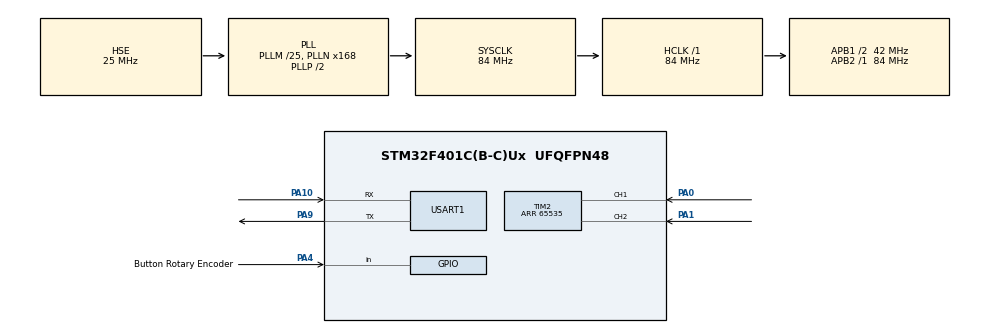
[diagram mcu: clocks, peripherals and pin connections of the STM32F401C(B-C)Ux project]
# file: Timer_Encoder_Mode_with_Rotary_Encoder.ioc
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Mcu.Family=STM32F4
RCC.PLLSourceVirtual=RCC_PLLSOURCE_HSE
RCC.CortexFreq_Value=84000000
PA10.Mode=Asynchronous
TIM2.IC1Filter=10
PH1\ -\ OSC_OUT.Mode=HSE-External-Oscillator
TIM2.EncoderMode=TIM_ENCODERMODE_TI12
RCC.APB1CLKDivider=RCC_HCLK_DIV2
RCC.SYSCLKSource=RCC_SYSCLKSOURCE_PLLCLK
ProjectManager.StackSize=0x400
PA0-WKUP.Signal=S_TIM2_CH1_ETR
PA13.Signal=SYS_JTMS-SWDIO
SH.S_TIM2_CH2.0=TIM2_CH2,Encoder_Interface
PA9.Mode=Asynchronous
PH0\ -\ OSC_IN.Mode=HSE-External-Oscillator
PH0\ -\ OSC_IN.Signal=RCC_OSC_IN
ProjectManager.TargetToolchain=STM32CubeIDE
RCC.HCLKFreq_Value=84000000
RCC.APB2TimFreq_Value=84000000
PA9.Signal=USART1_TX
RCC.LSE_VALUE=32768
PA1.Signal=S_TIM2_CH2
RCC.AHBFreq_Value=84000000
RCC.HSE_VALUE=25000000
PH1\ -\ OSC_OUT.Signal=RCC_OSC_OUT
board=custom
RCC.VCOOutputFreq_Value=168000000
RCC.APB2Freq_Value=84000000
PA14.Mode=Serial_Wire
TIM2.Period=65535
PA13.Mode=Serial_Wire
Mcu.Name=STM32F401C(B-C)Ux
RCC.48MHZClocksFreq_Value=42000000
PA4.Signal=GPIO_Input
RCC.SYSCLKFreq_VALUE=84000000
Mcu.Package=UFQFPN48
USART1.VirtualMode=VM_ASYNC
SH.S_TIM2_CH1_ETR.0=TIM2_CH1,Encoder_Interface
PA10.Signal=USART1_RX
PA14.Signal=SYS_JTCK-SWCLK
ProjectManager.HeapSize=0x200
RCC.HSI_VALUE=16000000
NVIC.PriorityGroup=NVIC_PRIORITYGROUP_4
RCC.PLLM=25
RCC.PLLN=168
RCC.APB1TimFreq_Value=84000000
TIM2.AutoReloadPreload=TIM_AUTORELOAD_PRELOAD_ENABLE
RCC.APB1Freq_Value=42000000
PA4.GPIO_Label=Button Rotary Encoder
TIM2.IC2Filter=10

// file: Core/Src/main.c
/* USER CODE BEGIN Header */
/**
  ******************************************************************************
  * @file           : main.c
  * @brief          : Main program body
  ******************************************************************************
  * @attention
  *
  * <h2><center>&copy; Copyright (c) 2023 STMicroelectronics.
  * All rights reserved.</center></h2>
  *
  * This software component is licensed by ST under BSD 3-Clause license,
  * the "License"; You may not use this file except in compliance with the
  * License. You may obtain a copy of the License at:
  *                        opensource.org/licenses/BSD-3-Clause
  *
  ******************************************************************************
  */
/* USER CODE END Header */
#include "main.h"

TIM_HandleTypeDef htim2;

UART_HandleTypeDef huart1;

void SystemClock_Config(void);
static void MX_GPIO_Init(void);
static void MX_TIM2_Init(void);
static void MX_USART1_UART_Init(void);

int main(void)
{
  /* USER CODE BEGIN 1 */

		uint8_t message[50] = {'\0'};

  /* USER CODE END 1 */

  /* MCU Configuration--------------------------------------------------------*/

  /* Reset of all peripherals, Initializes the Flash interface and the Systick. */
  HAL_Init();

  /* Configure the system clock */
  SystemClock_Config();

  /* Initialize all configured peripherals */
  MX_GPIO_Init();
  MX_TIM2_Init();
  MX_USART1_UART_Init();
  /* USER CODE BEGIN 2 */

  	  HAL_TIM_Encoder_Start(&htim2, TIM_CHANNEL_ALL);

  /* USER CODE END 2 */

  /* Infinite loop */
  while (1)
  {

    /* USER CODE BEGIN 3 */

	  	  	  	if(HAL_GPIO_ReadPin (GPIOA, GPIO_PIN_4))
	            {
	                sprintf(message, "Switch Released, Encoder Ticks = %d\n\r", ((TIM2->CNT)>>2));
	               // HAL_UART_Transmit(&huart2, message, sizeof(message), 100);
	            }
	            else
	            {
	                sprintf(message, "Switch Pressed,  Encoder Ticks = %d\n\r", ((TIM2->CNT)>>2));
	              //  HAL_UART_Transmit(&huart2, message, sizeof(message), 100);
	            }
	            HAL_Delay(100);

  }
  /* USER CODE END 3 */
}

void SystemClock_Config(void)
{
  RCC_OscInitTypeDef RCC_OscInitStruct = {0};
  RCC_ClkInitTypeDef RCC_ClkInitStruct = {0};

  /** Configure the main internal regulator output voltage
  */
  __HAL_RCC_PWR_CLK_ENABLE();
  __HAL_PWR_VOLTAGESCALING_CONFIG(PWR_REGULATOR_VOLTAGE_SCALE2);
  /** Initializes the RCC Oscillators according to the specified parameters
  * in the RCC_OscInitTypeDef structure.
  */
  RCC_OscInitStruct.OscillatorType = RCC_OSCILLATORTYPE_HSE;
  RCC_OscInitStruct.HSEState = RCC_HSE_ON;
  RCC_OscInitStruct.PLL.PLLState = RCC_PLL_ON;
  RCC_OscInitStruct.PLL.PLLSource = RCC_PLLSOURCE_HSE;
  RCC_OscInitStruct.PLL.PLLM = 25;
  RCC_OscInitStruct.PLL.PLLN = 168;
  RCC_OscInitStruct.PLL.PLLP = RCC_PLLP_DIV2;
  RCC_OscInitStruct.PLL.PLLQ = 4;
  if (HAL_RCC_OscConfig(&RCC_OscInitStruct) != HAL_OK)
  {
    Error_Handler();
  }
  /** Initializes the CPU, AHB and APB buses clocks
  */
  RCC_ClkInitStruct.ClockType = RCC_CLOCKTYPE_HCLK|RCC_CLOCKTYPE_SYSCLK
                              |RCC_CLOCKTYPE_PCLK1|RCC_CLOCKTYPE_PCLK2;
  RCC_ClkInitStruct.SYSCLKSource = RCC_SYSCLKSOURCE_PLLCLK;
  RCC_ClkInitStruct.AHBCLKDivider = RCC_SYSCLK_DIV1;
  RCC_ClkInitStruct.APB1CLKDivider = RCC_HCLK_DIV2;
  RCC_ClkInitStruct.APB2CLKDivider = RCC_HCLK_DIV1;

  if (HAL_RCC_ClockConfig(&RCC_ClkInitStruct, FLASH_LATENCY_2) != HAL_OK)
  {
    Error_Handler();
  }
}

static void MX_TIM2_Init(void)
{

  TIM_Encoder_InitTypeDef sConfig = {0};
  TIM_MasterConfigTypeDef sMasterConfig = {0};

  htim2.Instance = TIM2;
  htim2.Init.Prescaler = 0;
  htim2.Init.CounterMode = TIM_COUNTERMODE_UP;
  htim2.Init.Period = 65535;
  htim2.Init.ClockDivision = TIM_CLOCKDIVISION_DIV1;
  htim2.Init.AutoReloadPreload = TIM_AUTORELOAD_PRELOAD_ENABLE;
  sConfig.EncoderMode = TIM_ENCODERMODE_TI12;
  sConfig.IC1Polarity = TIM_ICPOLARITY_RISING;
  sConfig.IC1Selection = TIM_ICSELECTION_DIRECTTI;
  sConfig.IC1Prescaler = TIM_ICPSC_DIV1;
  sConfig.IC1Filter = 10;
  sConfig.IC2Polarity = TIM_ICPOLARITY_RISING;
  sConfig.IC2Selection = TIM_ICSELECTION_DIRECTTI;
  sConfig.IC2Prescaler = TIM_ICPSC_DIV1;
  sConfig.IC2Filter = 10;
  if (HAL_TIM_Encoder_Init(&htim2, &sConfig) != HAL_OK)
  {
    Error_Handler();
  }
  sMasterConfig.MasterOutputTrigger = TIM_TRGO_RESET;
  sMasterConfig.MasterSlaveMode = TIM_MASTERSLAVEMODE_DISABLE;
  if (HAL_TIMEx_MasterConfigSynchronization(&htim2, &sMasterConfig) != HAL_OK)
  {
    Error_Handler();
  }

}

static void MX_USART1_UART_Init(void)
{

  huart1.Instance = USART1;
  huart1.Init.BaudRate = 115200;
  huart1.Init.WordLength = UART_WORDLENGTH_8B;
  huart1.Init.StopBits = UART_STOPBITS_1;
  huart1.Init.Parity = UART_PARITY_NONE;
  huart1.Init.Mode = UART_MODE_TX_RX;
  huart1.Init.HwFlowCtl = UART_HWCONTROL_NONE;
  huart1.Init.OverSampling = UART_OVERSAMPLING_16;
  if (HAL_UART_Init(&huart1) != HAL_OK)
  {
    Error_Handler();
  }

}

static void MX_GPIO_Init(void)
{
  GPIO_InitTypeDef GPIO_InitStruct = {0};

  /* GPIO Ports Clock Enable */
  __HAL_RCC_GPIOH_CLK_ENABLE();
  __HAL_RCC_GPIOA_CLK_ENABLE();

  /*Configure GPIO pin : Button_Rotary_Encoder_Pin */
  GPIO_InitStruct.Pin = Button_Rotary_Encoder_Pin;
  GPIO_InitStruct.Mode = GPIO_MODE_INPUT;
  GPIO_InitStruct.Pull = GPIO_NOPULL;
  HAL_GPIO_Init(Button_Rotary_Encoder_GPIO_Port, &GPIO_InitStruct);

}

void Error_Handler(void)
{
  __disable_irq();
  while (1)
  {
  }
}

/************************ (C) COPYRIGHT STMicroelectronics *****END OF FILE****/
